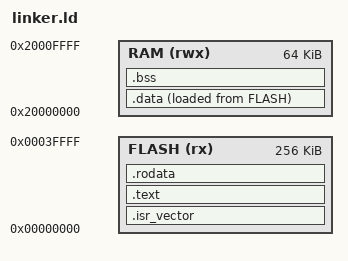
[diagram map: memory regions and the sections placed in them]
ENTRY(Reset_Handler)

MEMORY {
    FLASH (rx) : ORIGIN = 0x00000000, LENGTH = 256K
    RAM (rwx) : ORIGIN = 0x20000000, LENGTH = 64K
}

_estack = ORIGIN(RAM) + LENGTH(RAM);

SECTIONS {

    .isr_vector : {
        . = ALIGN(4);
        KEEP(*(.isr_vector))
        . = ALIGN(4);
    } > FLASH

    .text : {
        . = ALIGN(4);
        *(.text)
        *(.text*)
        . = ALIGN(4);
    } > FLASH

    .rodata : {
        . = ALIGN(4);
        *(.rodata)
        *(.rodata*)
        . = ALIGN(4);
    } > FLASH

    _sidata = LOADADDR(.data);

    .data : {
        . = ALIGN(4);
        _sdata = .;
        *(.data)
        *(.data*)
        . = ALIGN(4);
        _edata = .;
    } > RAM AT > FLASH

    .bss : {
        . = ALIGN(4);
        _sbss = .;
        *(.bss)
        *(.bss*)
        . = ALIGN(4);
        _ebss = .;
    } > RAM
}

/*
    isr_vector -> Vector Table at 0x00000000

    _estack -> Pointer to end of stack
    _sidata -> Pointer to data segment (flash)
    _sdata -> Pointer to start of data
    _edata -> Pointer to end of data
    _sbss -> Pointer to start of bss
    _ebss -> Pointer to end of bss

*/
